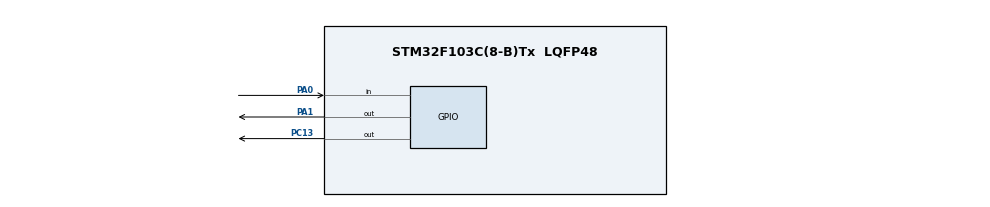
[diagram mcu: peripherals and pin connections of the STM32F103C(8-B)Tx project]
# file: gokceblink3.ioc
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Mcu.Family=STM32F1
Mcu.Name=STM32F103C(8-B)Tx
Mcu.Package=LQFP48
NVIC.PriorityGroup=NVIC_PRIORITYGROUP_4
PA0-WKUP.GPIO_PuPd=GPIO_PULLUP
PA0-WKUP.Signal=GPIO_Input
PA1.Signal=GPIO_Output
PA13.Mode=Serial_Wire
PA13.Signal=SYS_JTMS-SWDIO
PA14.Mode=Serial_Wire
PA14.Signal=SYS_JTCK-SWCLK
PC13-TAMPER-RTC.Signal=GPIO_Output
ProjectManager.HeapSize=0x200
ProjectManager.StackSize=0x400
ProjectManager.TargetToolchain=CMake
RCC.APB1Freq_Value=8000000
RCC.APB2Freq_Value=8000000
TIM2.Period=999
TIM2.Prescaler=7999
VP_TIM2_VS_ClockSourceINT.Mode=Internal
board=custom

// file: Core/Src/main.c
/* USER CODE BEGIN Header */
/**
  ******************************************************************************
  * @file           : main.c
  * @brief          : Main program body
  ******************************************************************************
  * @attention
  *
  * Copyright (c) 2026 STMicroelectronics.
  * All rights reserved.
  *
  * This software is licensed under terms that can be found in the LICENSE file
  * in the root directory of this software component.
  * If no LICENSE file comes with this software, it is provided AS-IS.
  *
  ******************************************************************************
  */
/* USER CODE END Header */
#include "main.h"

TIM_HandleTypeDef htim2;

/* USER CODE BEGIN PV */
uint16_t blink_count = 4;
uint16_t current_blink = 0;
uint8_t  system_state = 0;
uint32_t timer_counter = 0;
uint32_t button_timer = 0;

volatile uint8_t update_flash_flag = 0;

/* USER CODE END PV */

void SystemClock_Config(void);
static void MX_GPIO_Init(void);
static void MX_TIM2_Init(void);

/* USER CODE BEGIN 0 */
#define FLASH_ADDR 0x0800FC00

void Flash_Write(uint16_t value) {
    HAL_FLASH_Unlock();
    FLASH_EraseInitTypeDef EraseInitStruct;
    EraseInitStruct.TypeErase   = FLASH_TYPEERASE_PAGES;
    EraseInitStruct.PageAddress = FLASH_ADDR;
    EraseInitStruct.NbPages     = 1;
    uint32_t PageError;
    HAL_FLASHEx_Erase(&EraseInitStruct, &PageError);
    HAL_FLASH_Program(FLASH_TYPEPROGRAM_HALFWORD, FLASH_ADDR, value);
    HAL_FLASH_Lock();
}

uint16_t Flash_Read(void) {
    return *(uint16_t*)FLASH_ADDR;
}
/* USER CODE END 0 */

int main(void)
{
    HAL_Init();
    SystemClock_Config();
    MX_GPIO_Init();
    MX_TIM2_Init();

/* USER CODE BEGIN 2 */

blink_count = Flash_Read();
if (blink_count < 4 || blink_count > 7) {
blink_count = 4;
Flash_Write(blink_count);
}

HAL_GPIO_WritePin(GPIOA, GPIO_PIN_1, GPIO_PIN_RESET);

HAL_Delay(500);
if (HAL_GPIO_ReadPin(GPIOA, GPIO_PIN_0) == GPIO_PIN_RESET)
{
HAL_GPIO_WritePin(GPIOC, GPIO_PIN_13, GPIO_PIN_RESET);

HAL_Delay(3000);

if (HAL_GPIO_ReadPin(GPIOA, GPIO_PIN_0) == GPIO_PIN_RESET)
{
blink_count = 4;
Flash_Write(blink_count);
}
HAL_GPIO_WritePin(GPIOC, GPIO_PIN_13, GPIO_PIN_SET);
while (HAL_GPIO_ReadPin(GPIOA, GPIO_PIN_0) == GPIO_PIN_RESET)
{
}
HAL_Delay(100);
}
HAL_TIM_Base_Start_IT(&htim2);

/* USER CODE END 2 */

    while (1)
    {
        /* USER CODE BEGIN 3 */

        if (update_flash_flag == 1)
        {
            Flash_Write(blink_count);
            update_flash_flag = 0;
        }

        /* USER CODE END 3 */
    }
}

/* USER CODE BEGIN 4 */
void HAL_TIM_PeriodElapsedCallback(TIM_HandleTypeDef *htim)
{
    if (htim->Instance == TIM2)
    {
        /* ----------------------------------------------------------
         * ---------------------------------------------------------- */
        if (HAL_GPIO_ReadPin(GPIOA, GPIO_PIN_0) == GPIO_PIN_RESET)
        {
            button_timer++;
        }
        else
        {
            if (button_timer > 0)
            {
                blink_count++;
                if (blink_count > 7) blink_count = 4;

                update_flash_flag = 1;
            }
            button_timer = 0;
        }

        /* ----------------------------------------------------------
         * ---------------------------------------------------------- */
        if (system_state == 0)
        {
            HAL_GPIO_TogglePin(GPIOC, GPIO_PIN_13);

            if (HAL_GPIO_ReadPin(GPIOC, GPIO_PIN_13) == GPIO_PIN_SET)
            {
                current_blink++;

                if (current_blink >= blink_count)
                {
                    system_state  = 1;
                    current_blink = 0;
                    timer_counter = 0;
                }
            }
        }
        else if (system_state == 1)
        {
            timer_counter++;
            if (timer_counter >= 5)
            {
                system_state  = 0;
                timer_counter = 0;
            }
        }
    }
}
/* USER CODE END 4 */

/**
  * @brief TIM2: 8MHz HSI, Prescaler=7999, Period=999 → tam 1 saniye kesme
  */
static void MX_TIM2_Init(void)
{
    htim2.Instance               = TIM2;
    htim2.Init.Prescaler         = 7999;
    htim2.Init.CounterMode       = TIM_COUNTERMODE_UP;
    htim2.Init.Period            = 999;
    htim2.Init.ClockDivision     = TIM_CLOCKDIVISION_DIV1;
    htim2.Init.AutoReloadPreload = TIM_AUTORELOAD_PRELOAD_DISABLE;
    HAL_TIM_Base_Init(&htim2);
}

/**
  * @brief GPIO: PC13 LED çıkış, PA0 buton girişi (pull-up), PA1 GND referansı
  */
static void MX_GPIO_Init(void)
{
    GPIO_InitTypeDef GPIO_InitStruct = {0};

    __HAL_RCC_GPIOC_CLK_ENABLE();
    __HAL_RCC_GPIOA_CLK_ENABLE();

    // PC13 — Dahili LED (aktif-düşük, başlangıçta kapalı)
    HAL_GPIO_WritePin(GPIOC, GPIO_PIN_13, GPIO_PIN_SET);
    GPIO_InitStruct.Pin   = GPIO_PIN_13;
    GPIO_InitStruct.Mode  = GPIO_MODE_OUTPUT_PP;
    GPIO_InitStruct.Pull  = GPIO_NOPULL;
    GPIO_InitStruct.Speed = GPIO_SPEED_FREQ_LOW;
    HAL_GPIO_Init(GPIOC, &GPIO_InitStruct);

    // PA0 — Buton girişi (dahili pull-up aktif)
    GPIO_InitStruct.Pin  = GPIO_PIN_0;
    GPIO_InitStruct.Mode = GPIO_MODE_INPUT;
    GPIO_InitStruct.Pull = GPIO_PULLUP;
    HAL_GPIO_Init(GPIOA, &GPIO_InitStruct);

    // PA1 — Lojik 0 referans hattı (h maddesi)
    HAL_GPIO_WritePin(GPIOA, GPIO_PIN_1, GPIO_PIN_RESET);
    GPIO_InitStruct.Pin   = GPIO_PIN_1;
    GPIO_InitStruct.Mode  = GPIO_MODE_OUTPUT_PP;
    GPIO_InitStruct.Pull  = GPIO_NOPULL;
    GPIO_InitStruct.Speed = GPIO_SPEED_FREQ_LOW;
    HAL_GPIO_Init(GPIOA, &GPIO_InitStruct);
}

void SystemClock_Config(void)
{
    RCC_OscInitTypeDef RCC_OscInitStruct = {0};
    RCC_ClkInitTypeDef RCC_ClkInitStruct = {0};

    RCC_OscInitStruct.OscillatorType      = RCC_OSCILLATORTYPE_HSI;
    RCC_OscInitStruct.HSIState            = RCC_HSI_ON;
    RCC_OscInitStruct.HSICalibrationValue = RCC_HSICALIBRATION_DEFAULT;
    RCC_OscInitStruct.PLL.PLLState        = RCC_PLL_NONE;
    HAL_RCC_OscConfig(&RCC_OscInitStruct);

    RCC_ClkInitStruct.ClockType      = RCC_CLOCKTYPE_HCLK | RCC_CLOCKTYPE_SYSCLK |
                                       RCC_CLOCKTYPE_PCLK1 | RCC_CLOCKTYPE_PCLK2;
    RCC_ClkInitStruct.SYSCLKSource   = RCC_SYSCLKSOURCE_HSI;
    RCC_ClkInitStruct.AHBCLKDivider  = RCC_SYSCLK_DIV1;
    RCC_ClkInitStruct.APB1CLKDivider = RCC_HCLK_DIV1;
    RCC_ClkInitStruct.APB2CLKDivider = RCC_HCLK_DIV1;
    HAL_RCC_ClockConfig(&RCC_ClkInitStruct, FLASH_LATENCY_0);
}

void Error_Handler(void)
{
    __disable_irq();
    while (1) {}
}
